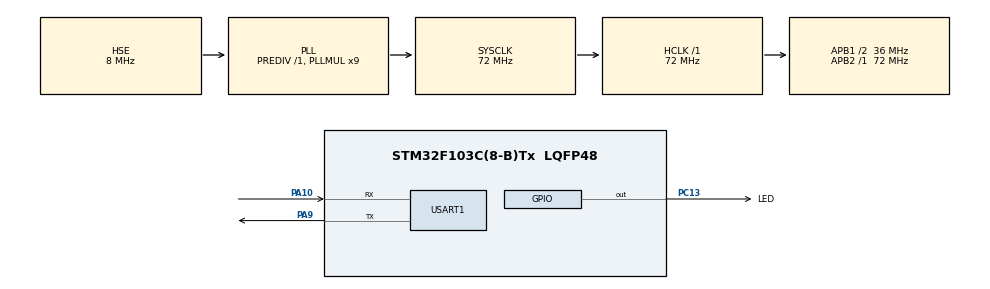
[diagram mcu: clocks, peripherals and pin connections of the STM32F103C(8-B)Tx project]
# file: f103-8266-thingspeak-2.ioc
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Mcu.Family=STM32F1
Mcu.Name=STM32F103C(8-B)Tx
Mcu.Package=LQFP48
NVIC.PriorityGroup=NVIC_PRIORITYGROUP_4
NVIC.USART1_IRQn=true\:1\:0\:true\:false\:true\:true\:true
PA10.Mode=Asynchronous
PA10.Signal=USART1_RX
PA13.Mode=Serial_Wire
PA13.Signal=SYS_JTMS-SWDIO
PA14.Mode=Serial_Wire
PA14.Signal=SYS_JTCK-SWCLK
PA9.Mode=Asynchronous
PA9.Signal=USART1_TX
PC13-TAMPER-RTC.GPIO_Label=LED
PC13-TAMPER-RTC.Signal=GPIO_Output
PD0-OSC_IN.Mode=HSE-External-Oscillator
PD0-OSC_IN.Signal=RCC_OSC_IN
PD1-OSC_OUT.Mode=HSE-External-Oscillator
PD1-OSC_OUT.Signal=RCC_OSC_OUT
ProjectManager.HeapSize=0x200
ProjectManager.StackSize=0x400
ProjectManager.TargetToolchain=STM32CubeIDE
RCC.AHBFreq_Value=72000000
RCC.APB1CLKDivider=RCC_HCLK_DIV2
RCC.APB1Freq_Value=36000000
RCC.APB1TimFreq_Value=72000000
RCC.APB2Freq_Value=72000000
RCC.APB2TimFreq_Value=72000000
RCC.HCLKFreq_Value=72000000
RCC.PLLMUL=RCC_PLL_MUL9
RCC.PLLSourceVirtual=RCC_PLLSOURCE_HSE
RCC.SYSCLKFreq_VALUE=72000000
RCC.SYSCLKSource=RCC_SYSCLKSOURCE_PLLCLK
RCC.USBFreq_Value=72000000
USART1.VirtualMode=VM_ASYNC
board=custom

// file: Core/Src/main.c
/* USER CODE BEGIN Header */
/**
  ******************************************************************************
  * @file           : main.c
  * @brief          : Main program body
  ******************************************************************************
  * @attention
  *
  * <h2><center>&copy; Copyright (c) 2021 STMicroelectronics.
  * All rights reserved.</center></h2>
  *
  * This software component is licensed by ST under BSD 3-Clause license,
  * the "License"; You may not use this file except in compliance with the
  * License. You may obtain a copy of the License at:
  *                        opensource.org/licenses/BSD-3-Clause
  *
  ******************************************************************************
  */
/* USER CODE END Header */
#include "main.h"

/* USER CODE BEGIN Includes */
#include <stdio.h>
/* USER CODE END Includes */

UART_HandleTypeDef huart1;

void SystemClock_Config(void);
static void MX_GPIO_Init(void);
static void MX_USART1_UART_Init(void);

/* USER CODE BEGIN 0 */
char sendBuff[64], sendBuff2[64];
uint8_t recArr[64], recData;
uint8_t buffLen, buffLen2, buffCnt = 0;
uint8_t count = 0;

const char API_KEY[] = "VXCBN7B47O7SPQAQ";
const char WIFI_NAME[] = "GxA50";
const char WIFI_PASSW[] = "iemx6540";

void HAL_UART_RxCpltCallback(UART_HandleTypeDef *huart)
{
	recArr[buffCnt++] = recData;
	if(buffCnt == 64) buffCnt = 0;
	HAL_UART_Receive_IT(&huart1, &recData, 1);
}
/* USER CODE END 0 */

int main(void)
{

  /* MCU Configuration--------------------------------------------------------*/

  /* Reset of all peripherals, Initializes the Flash interface and the Systick. */
  HAL_Init();

  /* Configure the system clock */
  SystemClock_Config();

  /* Initialize all configured peripherals */
  MX_GPIO_Init();
  MX_USART1_UART_Init();
  /* USER CODE BEGIN 2 */
  // Wifi Connection
  buffLen = sprintf(sendBuff, "AT+CWMODE_CUR=1\r\n");
  HAL_UART_Transmit(&huart1, (uint8_t *)sendBuff, buffLen, 1000);

  buffLen = sprintf(sendBuff, "AT+CWLAP\r\n");
  HAL_UART_Transmit(&huart1, (uint8_t *)sendBuff, buffLen, 1000);

  HAL_Delay(2000);

  buffLen = sprintf(sendBuff, "AT+CWJAP_CUR=\"%s\",\"%s\"\r\n", WIFI_NAME, WIFI_PASSW);
  HAL_UART_Transmit(&huart1, (uint8_t *)sendBuff, buffLen, 1000);

  /* USER CODE END 2 */

  /* Infinite loop */
  /* USER CODE BEGIN WHILE */
  while (1)
  {
	  HAL_GPIO_TogglePin(LED_GPIO_Port, LED_Pin);
	  HAL_Delay(500);
    /* USER CODE END WHILE */

    /* USER CODE BEGIN 3 */
	  count++;

	  // connect Thinkspeak server
	  buffLen = sprintf(sendBuff, "AT+CIPSTART=\"TCP\",\"api.thingspeak.com\",80\r\n");
	  HAL_UART_Transmit(&huart1, (uint8_t *)sendBuff, buffLen, 1000);
	  HAL_Delay(3000);

	  // after connection to Thingspeak prepare data to send
	  buffLen = sprintf(sendBuff, "GET /update?api_key=%s&field1=%d&field2=%d\r\n", API_KEY, count, count*2);
	  buffLen2 = sprintf(sendBuff2, "AT+CIPSEND=%d\r\n", buffLen);

	  // send preapeared buffers to Thingspeak using ESP8266
	  HAL_UART_Transmit(&huart1, (uint8_t *)sendBuff2, buffLen2, 1000);
	  HAL_Delay(1000);
	  HAL_UART_Transmit(&huart1, (uint8_t *)sendBuff, buffLen, 1000);

	  // wait for 30sn to send new data
	  HAL_Delay(15000);

  }
  /* USER CODE END 3 */
}

void SystemClock_Config(void)
{
  RCC_OscInitTypeDef RCC_OscInitStruct = {0};
  RCC_ClkInitTypeDef RCC_ClkInitStruct = {0};

  /** Initializes the RCC Oscillators according to the specified parameters
  * in the RCC_OscInitTypeDef structure.
  */
  RCC_OscInitStruct.OscillatorType = RCC_OSCILLATORTYPE_HSE;
  RCC_OscInitStruct.HSEState = RCC_HSE_ON;
  RCC_OscInitStruct.HSEPredivValue = RCC_HSE_PREDIV_DIV1;
  RCC_OscInitStruct.HSIState = RCC_HSI_ON;
  RCC_OscInitStruct.PLL.PLLState = RCC_PLL_ON;
  RCC_OscInitStruct.PLL.PLLSource = RCC_PLLSOURCE_HSE;
  RCC_OscInitStruct.PLL.PLLMUL = RCC_PLL_MUL9;
  if (HAL_RCC_OscConfig(&RCC_OscInitStruct) != HAL_OK)
  {
    Error_Handler();
  }
  /** Initializes the CPU, AHB and APB buses clocks
  */
  RCC_ClkInitStruct.ClockType = RCC_CLOCKTYPE_HCLK|RCC_CLOCKTYPE_SYSCLK
                              |RCC_CLOCKTYPE_PCLK1|RCC_CLOCKTYPE_PCLK2;
  RCC_ClkInitStruct.SYSCLKSource = RCC_SYSCLKSOURCE_PLLCLK;
  RCC_ClkInitStruct.AHBCLKDivider = RCC_SYSCLK_DIV1;
  RCC_ClkInitStruct.APB1CLKDivider = RCC_HCLK_DIV2;
  RCC_ClkInitStruct.APB2CLKDivider = RCC_HCLK_DIV1;

  if (HAL_RCC_ClockConfig(&RCC_ClkInitStruct, FLASH_LATENCY_2) != HAL_OK)
  {
    Error_Handler();
  }
}

static void MX_USART1_UART_Init(void)
{

  huart1.Instance = USART1;
  huart1.Init.BaudRate = 115200;
  huart1.Init.WordLength = UART_WORDLENGTH_8B;
  huart1.Init.StopBits = UART_STOPBITS_1;
  huart1.Init.Parity = UART_PARITY_NONE;
  huart1.Init.Mode = UART_MODE_TX_RX;
  huart1.Init.HwFlowCtl = UART_HWCONTROL_NONE;
  huart1.Init.OverSampling = UART_OVERSAMPLING_16;
  if (HAL_UART_Init(&huart1) != HAL_OK)
  {
    Error_Handler();
  }

}

static void MX_GPIO_Init(void)
{
  GPIO_InitTypeDef GPIO_InitStruct = {0};

  /* GPIO Ports Clock Enable */
  __HAL_RCC_GPIOC_CLK_ENABLE();
  __HAL_RCC_GPIOD_CLK_ENABLE();
  __HAL_RCC_GPIOA_CLK_ENABLE();

  /*Configure GPIO pin Output Level */
  HAL_GPIO_WritePin(LED_GPIO_Port, LED_Pin, GPIO_PIN_RESET);

  /*Configure GPIO pin : LED_Pin */
  GPIO_InitStruct.Pin = LED_Pin;
  GPIO_InitStruct.Mode = GPIO_MODE_OUTPUT_PP;
  GPIO_InitStruct.Pull = GPIO_NOPULL;
  GPIO_InitStruct.Speed = GPIO_SPEED_FREQ_LOW;
  HAL_GPIO_Init(LED_GPIO_Port, &GPIO_InitStruct);

}

void Error_Handler(void)
{
  __disable_irq();
  while (1)
  {
  }
}

/************************ (C) COPYRIGHT STMicroelectronics *****END OF FILE****/
